AUTOSAR XML (schema 4-3-0)
package /Impl_SWC_FDC_ARPkg
  swc implementation Impl_SWC_FDC_type: programming-language=C, sw-version=1.0.0, vendor-id=0, behavior=SWC_FDC_type_IB
    code-descriptors:
      code SRC: artifact-descriptors=autosar-engineering-object={short-label=EngObject, category=SWSRC}
    resource consumption ResourceConsumption
      memory section MEM_SWC_FDC_CAL: size=0, sw-addrmethod=CAL, symbol=CAL
      memory section MEM_SWC_FDC_CODE: size=0, sw-addrmethod=CODE, symbol=CODE
package /SWC_FDC_ARPkg
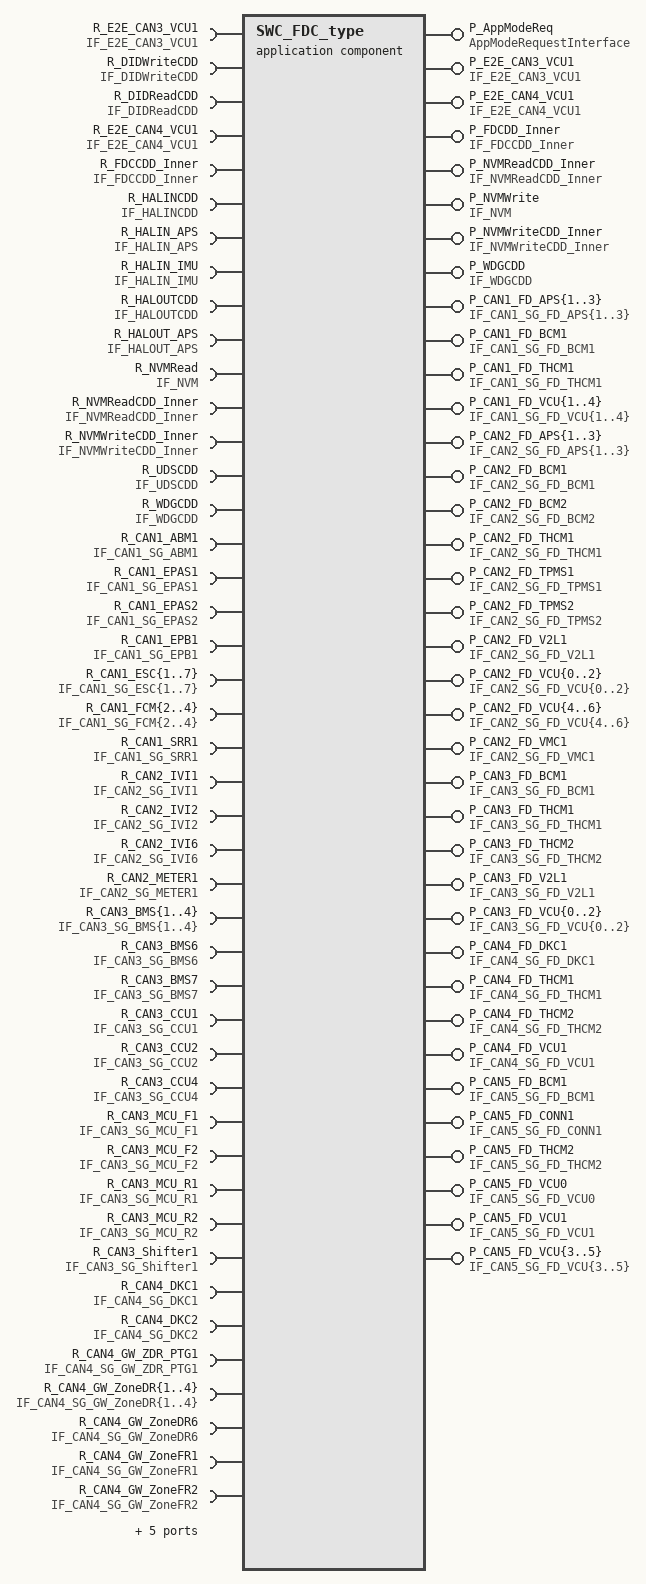
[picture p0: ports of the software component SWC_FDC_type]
  application sw component type SWC_FDC_type
    52 x provide port:
      P_AppModeReq: provided-interface=AppModeRequestInterface
      P_E2E_CAN3_VCU1: provided-interface=IF_E2E_CAN3_VCU1
      P_E2E_CAN4_VCU1: provided-interface=IF_E2E_CAN4_VCU1
      P_FDCDD_Inner: provided-interface=IF_FDCCDD_Inner
      P_NVMReadCDD_Inner: provided-interface=IF_NVMReadCDD_Inner
      P_NVMWrite: nv-provide-com-spec{ram-block-init-value=ValueSpecification_:256 x 0, rom-block-init-value=ValueSpecification_:256 x 0, variable=NV_FVTDataArray}, provided-interface=IF_NVM
      P_NVMWriteCDD_Inner: provided-interface=IF_NVMWriteCDD_Inner
      P_WDGCDD: provided-interface=IF_WDGCDD
      P_CAN1_FD_APS{1..3}: provided-interface=IF_CAN1_SG_FD_APS{1..3}
      P_CAN1_FD_BCM1: provided-interface=IF_CAN1_SG_FD_BCM1
      P_CAN1_FD_THCM1: provided-interface=IF_CAN1_SG_FD_THCM1
      P_CAN1_FD_VCU{1..4}: provided-interface=IF_CAN1_SG_FD_VCU{1..4}
      P_CAN2_FD_APS{1..3}: provided-interface=IF_CAN2_SG_FD_APS{1..3}
      P_CAN2_FD_BCM1: provided-interface=IF_CAN2_SG_FD_BCM1
      P_CAN2_FD_BCM2: provided-interface=IF_CAN2_SG_FD_BCM2
      P_CAN2_FD_THCM1: provided-interface=IF_CAN2_SG_FD_THCM1
      P_CAN2_FD_TPMS1: provided-interface=IF_CAN2_SG_FD_TPMS1
      P_CAN2_FD_TPMS2: provided-interface=IF_CAN2_SG_FD_TPMS2
      P_CAN2_FD_V2L1: provided-interface=IF_CAN2_SG_FD_V2L1
      P_CAN2_FD_VCU{0..2}: provided-interface=IF_CAN2_SG_FD_VCU{0..2}
      P_CAN2_FD_VCU{4..6}: provided-interface=IF_CAN2_SG_FD_VCU{4..6}
      P_CAN2_FD_VMC1: provided-interface=IF_CAN2_SG_FD_VMC1
      P_CAN3_FD_BCM1: provided-interface=IF_CAN3_SG_FD_BCM1
      P_CAN3_FD_THCM1: provided-interface=IF_CAN3_SG_FD_THCM1
      P_CAN3_FD_THCM2: provided-interface=IF_CAN3_SG_FD_THCM2
      P_CAN3_FD_V2L1: provided-interface=IF_CAN3_SG_FD_V2L1
      P_CAN3_FD_VCU{0..2}: provided-interface=IF_CAN3_SG_FD_VCU{0..2}
      P_CAN4_FD_DKC1: provided-interface=IF_CAN4_SG_FD_DKC1
      P_CAN4_FD_THCM1: provided-interface=IF_CAN4_SG_FD_THCM1
      P_CAN4_FD_THCM2: provided-interface=IF_CAN4_SG_FD_THCM2
      P_CAN4_FD_VCU1: provided-interface=IF_CAN4_SG_FD_VCU1
      P_CAN5_FD_BCM1: provided-interface=IF_CAN5_SG_FD_BCM1
      P_CAN5_FD_CONN1: provided-interface=IF_CAN5_SG_FD_CONN1
      P_CAN5_FD_THCM2: provided-interface=IF_CAN5_SG_FD_THCM2
      P_CAN5_FD_VCU0: provided-interface=IF_CAN5_SG_FD_VCU0
      P_CAN5_FD_VCU1: provided-interface=IF_CAN5_SG_FD_VCU1
      P_CAN5_FD_VCU{3..5}: provided-interface=IF_CAN5_SG_FD_VCU{3..5}
    63 x require port:
      R_E2E_CAN3_VCU1: required-interface=IF_E2E_CAN3_VCU1
      R_DIDWriteCDD: required-interface=IF_DIDWriteCDD
      R_DIDReadCDD: required-interface=IF_DIDReadCDD
      R_E2E_CAN4_VCU1: required-interface=IF_E2E_CAN4_VCU1
      R_FDCCDD_Inner: required-interface=IF_FDCCDD_Inner
      R_HALINCDD: required-interface=IF_HALINCDD
      R_HALIN_APS: required-interface=IF_HALIN_APS
      R_HALIN_IMU: required-interface=IF_HALIN_IMU
      R_HALOUTCDD: required-interface=IF_HALOUTCDD
      R_HALOUT_APS: required-interface=IF_HALOUT_APS
      R_NVMRead: nv-require-com-spec{init-value=256 x 0, variable=NV_FVTDataArray}, required-interface=IF_NVM
      R_NVMReadCDD_Inner: required-interface=IF_NVMReadCDD_Inner
      R_NVMWriteCDD_Inner: required-interface=IF_NVMWriteCDD_Inner
      R_UDSCDD: required-interface=IF_UDSCDD
      R_WDGCDD: required-interface=IF_WDGCDD
      R_CAN1_ABM1: required-interface=IF_CAN1_SG_ABM1
      R_CAN1_EPAS1: required-interface=IF_CAN1_SG_EPAS1
      R_CAN1_EPAS2: required-interface=IF_CAN1_SG_EPAS2
      R_CAN1_EPB1: required-interface=IF_CAN1_SG_EPB1
      R_CAN1_ESC{1..7}: required-interface=IF_CAN1_SG_ESC{1..7}
      R_CAN1_FCM{2..4}: required-interface=IF_CAN1_SG_FCM{2..4}
      R_CAN1_SRR1: required-interface=IF_CAN1_SG_SRR1
      R_CAN2_IVI1: required-interface=IF_CAN2_SG_IVI1
      R_CAN2_IVI2: required-interface=IF_CAN2_SG_IVI2
      R_CAN2_IVI6: required-interface=IF_CAN2_SG_IVI6
      R_CAN2_METER1: required-interface=IF_CAN2_SG_METER1
      R_CAN3_BMS{1..4}: required-interface=IF_CAN3_SG_BMS{1..4}
      R_CAN3_BMS6: required-interface=IF_CAN3_SG_BMS6
      R_CAN3_BMS7: required-interface=IF_CAN3_SG_BMS7
      R_CAN3_CCU1: required-interface=IF_CAN3_SG_CCU1
      R_CAN3_CCU2: required-interface=IF_CAN3_SG_CCU2
      R_CAN3_CCU4: required-interface=IF_CAN3_SG_CCU4
      R_CAN3_MCU_F1: required-interface=IF_CAN3_SG_MCU_F1
      R_CAN3_MCU_F2: required-interface=IF_CAN3_SG_MCU_F2
      R_CAN3_MCU_R1: required-interface=IF_CAN3_SG_MCU_R1
      R_CAN3_MCU_R2: required-interface=IF_CAN3_SG_MCU_R2
      R_CAN3_Shifter1: required-interface=IF_CAN3_SG_Shifter1
      R_CAN4_DKC1: required-interface=IF_CAN4_SG_DKC1
      R_CAN4_DKC2: required-interface=IF_CAN4_SG_DKC2
      R_CAN4_GW_ZDR_PTG1: required-interface=IF_CAN4_SG_GW_ZDR_PTG1
      R_CAN4_GW_ZoneDR{1..4}: required-interface=IF_CAN4_SG_GW_ZoneDR{1..4}
      R_CAN4_GW_ZoneDR6: required-interface=IF_CAN4_SG_GW_ZoneDR6
      R_CAN4_GW_ZoneFR1: required-interface=IF_CAN4_SG_GW_ZoneFR1
      R_CAN4_GW_ZoneFR2: required-interface=IF_CAN4_SG_GW_ZoneFR2
      R_CAN4_Zone_Dr_SCP: required-interface=IF_CAN4_SG_Zone_Dr_SCP
      R_CAN4_Zone_Dr_THCM: required-interface=IF_CAN4_SG_Zone_Dr_THCM
      R_CAN4_Zone_Dr_VCU: required-interface=IF_CAN4_SG_Zone_Dr_VCU
      R_CAN4_Zone_Fr_THCM: required-interface=IF_CAN4_SG_Zone_Fr_THCM
      R_CAN5_TBOX1: required-interface=IF_CAN5_SG_TBOX1
    behavior SWC_FDC_type_IB: data-type-mapping=AppModeTypeMap, handle-termination-and-restart=NO-SUPPORT
      9 x timing event:
        TE_100ms: start-on-event=run_SWC_FDC_Tx_100ms, period=0.1
        TE_20ms: start-on-event=run_SWC_FDC_Tx_20ms, period=0.02
        TE_500ms: start-on-event=run_SWC_FDC_Tx_500ms, period=0.5
        TE_5000ms: start-on-event=run_SWC_FDC_Tx_5000ms, period=5
        TE_10ms: start-on-event=run_SWC_FDC_Tx_10ms, period=0.01
        TE_5ms: start-on-event=run_SWC_FDC_RxTx_5ms, period=0.005
        TE_CDD_10ms: start-on-event=run_SWC_FDC_CDD_10ms, period=0.01
        TE_PAS_1ms: start-on-event=run_SWC_FDC_PAS_1ms, period=0.001
        TE_UDS_10ms: start-on-event=run_SWC_FDC_UDS_10ms, period=0.01
      8 x operation invoked event:
        oie_P_E2E_CAN3_VCU1_CSOP_Write_CAN3_VCU1: start-on-event=run_SWC_FDC_E2E_Write_CAN3VCU1, operation=P_E2E_CAN3_VCU1.CSOP_Write_CAN3_VCU1
        oie_P_E2E_CAN4_VCU1_CSOP_Write_CAN4_VCU1: start-on-event=run_SWC_FDC_E2E_Write_CAN4VCU1, operation=P_E2E_CAN4_VCU1.CSOP_Write_CAN4_VCU1
        oie_P_FDCDD_Inner_CSOP_FDC_AppCallSleep: start-on-event=run_SWC_FDC_AppCallSleep, operation=P_FDCDD_Inner.CSOP_FDC_AppCallSleep
        oie_P_NVMReadCDD_Inner_NVM_ReadOperation: start-on-event=run_SWC_FDC_NvmRead, operation=P_NVMReadCDD_Inner.NVM_ReadOperation
        oie_P_NVMWriteCDD_Inner_NVM_WriteOperation: start-on-event=run_SWC_FDC_NvmWrite, operation=P_NVMWriteCDD_Inner.NVM_WriteOperation
        oie_P_WDGCDD_CSOP_Call_WDG_AppEnd: start-on-event=run_SWC_FDC_AppCallWDG_End, operation=P_WDGCDD.CSOP_Call_WDG_AppEnd
        oie_P_WDGCDD_CSOP_Call_WDG_AppStart: start-on-event=run_SWC_FDC_AppCallWDG_StartUp, operation=P_WDGCDD.CSOP_Call_WDG_AppStart
        oie_P_WDGCDD_CSOP_Call_Watchdog: start-on-event=run_SWC_FDC_AppCallWDG, operation=P_WDGCDD.CSOP_Call_Watchdog
      explicit-inter-runnable-variables:
        50 x data:
          IRV_ms10_CAN1_SG_FD_APS3: type=DT_CAN1_SG_FD_APS3
          IRV_ms10_CAN1_SG_FD_VCU2: type=DT_CAN1_SG_FD_VCU2
          IRV_ms10_CAN1_SG_FD_VCU3: type=DT_CAN1_SG_FD_VCU3
          IRV_ms10_CAN2_SG_FD_APS3: type=DT_CAN2_SG_FD_APS3
          IRV_ms10_CAN2_SG_FD_VCU2: type=DT_CAN2_SG_FD_VCU2
          IRV_ms10_CAN3_SG_FD_VCU0: type=DT_CAN3_SG_FD_VCU0
          IRV_ms10_CAN3_SG_FD_VCU2: type=DT_CAN3_SG_FD_VCU2
          IRV_ms10_CAN5_SG_FD_VCU3: type=DT_CAN5_SG_FD_VCU3
          IRV_ms100_CAN{1..4}_SG_FD_THCM1: type=DT_CAN{1..4}_SG_FD_THCM1
          IRV_ms20_CAN1_SG_FD_APS1: type=DT_CAN1_SG_FD_APS1
          IRV_ms20_CAN1_SG_FD_APS2: type=DT_CAN1_SG_FD_APS2
          IRV_ms20_CAN2_SG_FD_APS1: type=DT_CAN2_SG_FD_APS1
          IRV_ms20_CAN2_SG_FD_APS2: type=DT_CAN2_SG_FD_APS2
          IRV_ms500_CAN2_SG_FD_VCU5: type=DT_CAN2_SG_FD_VCU5
          IRV_ms500_CAN5_SG_FD_VCU5: type=DT_CAN5_SG_FD_VCU5
          IRV_ms5000_CAN2_SG_FD_VCU6: type=DT_CAN2_SG_FD_VCU6
          IRV_E2E_CAN3_SG_FD_VCU1: type=DT_CAN3_SG_FD_VCU1
          IRV_E2E_CAN4_SG_FD_VCU1: type=DT_CAN4_SG_FD_VCU1
          IRV_f32_ApsOutVehSpdSig: type=float32
          IRV_u16Array4_ApsInDist: type=u16_APSArray4_type
          IRV_u8Array12_ApsInUssSta: type=u8_USSArray12_type
          IRV_u8Array256_NvmReadArray: type=u8_FVTNVMArray256_type
          IRV_u8Array256_NvmWriteArray: type=u8_FVTNVMArray256_type
          IRV_u8Array8_ApsInLevel: type=u8_APSLevelArray8_type
          IRV_u8Array8_PasInDist: type=u8_PASArray8_type
          IRV_u8Array9_TPMSData: type=u8_TPMSDataArray9_type
          IRV_u8_ApsInPASChime: type=uint8
          IRV_u8_ApsInSensorLayout: type=uint8
          IRV_u8_ApsInSysFailSta: type=uint8
          IRV_u8_ApsInSysMode: type=uint8
          IRV_u8_ApsOutGearPosnSig: type=uint8
          IRV_u8_ApsOutSendChrgPlugSta: type=uint8
          IRV_u8_ApsOutSetFrSensorOnCmd: type=uint8
          IRV_u8_ApsOutSetFrSensorSwTOCmd: type=uint8
          IRV_u8_ApsOutSetVehSpdTOCmd: type=uint8
          IRV_u8_CTDSW: type=uint8
          IRV_u8_CrashSignal: type=uint8
          IRV_u8_DrDoorSW: type=uint8
          IRV_u8_HazardSW: type=uint8
          IRV_u8_HoodSW: type=uint8
          IRV_u8_PsDoorSW: type=uint8
          IRV_u8_RLDoorSW: type=uint8
          IRV_u8_RRDoorSW: type=uint8
          IRV_u8_SeatSW: type=uint8
          IRV_u8_TPMSDataInSta: type=boolean
          IRV_u8_TailgateSW: type=uint8
          IRV_u8_TrunkHanSW: type=uint8
      port-api-options:
        enable-take-address=false, indirect-api=false, port=P_FDCDD_Inner
        enable-take-address=false, indirect-api=false, port=P_NVMReadCDD_Inner
        enable-take-address=false, indirect-api=false, port=P_NVMWriteCDD_Inner
        enable-take-address=false, indirect-api=false, port=P_E2E_CAN3_VCU1
        enable-take-address=false, indirect-api=false, port=P_E2E_CAN4_VCU1
        enable-take-address=false, indirect-api=false, port=P_WDGCDD
      17 x runnable:
        run_SWC_FDC_Tx_100ms
          data-send-points:
            4 x access:
              dsp_CAN{1..4}_SG_FD_THCM1: accessed-variable=P_CAN{1..4}_FD_THCM1.CAN{1..4}_SG_FD_THCM1
          read-local-variables:
            4 x access:
              IRV_ms100_CAN{1..4}_SG_FD_THCM1: accessed-variable=IRV_ms100_CAN{1..4}_SG_FD_THCM1
        run_SWC_FDC_Tx_20ms
          data-send-points:
            4 x access:
              dsp_CAN1_SG_FD_APS1: accessed-variable=P_CAN1_FD_APS1.CAN1_SG_FD_APS1
              dsp_CAN1_SG_FD_APS2: accessed-variable=P_CAN1_FD_APS2.CAN1_SG_FD_APS2
              dsp_CAN2_SG_FD_APS1: accessed-variable=P_CAN2_FD_APS1.CAN2_SG_FD_APS1
              dsp_CAN2_SG_FD_APS2: accessed-variable=P_CAN2_FD_APS2.CAN2_SG_FD_APS2
          read-local-variables:
            4 x access:
              IRV_ms20_CAN1_SG_FD_APS1: accessed-variable=IRV_ms20_CAN1_SG_FD_APS1
              IRV_ms20_CAN1_SG_FD_APS2: accessed-variable=IRV_ms20_CAN1_SG_FD_APS2
              IRV_ms20_CAN2_SG_FD_APS1: accessed-variable=IRV_ms20_CAN2_SG_FD_APS1
              IRV_ms20_CAN2_SG_FD_APS2: accessed-variable=IRV_ms20_CAN2_SG_FD_APS2
        run_SWC_FDC_Tx_500ms
          data-send-points:
            access dsp_CAN2_SG_FD_VCU5: accessed-variable=P_CAN2_FD_VCU5.CAN2_SG_FD_VCU5
            access dsp_CAN5_SG_FD_VCU5: accessed-variable=P_CAN5_FD_VCU5.CAN5_SG_FD_VCU5
          read-local-variables:
            access IRV_ms500_CAN2_SG_FD_VCU5: accessed-variable=IRV_ms500_CAN2_SG_FD_VCU5
            access IRV_ms500_CAN5_SG_FD_VCU5: accessed-variable=IRV_ms500_CAN5_SG_FD_VCU5
        run_SWC_FDC_Tx_5000ms
          data-send-points:
            access dsp_CAN2_SG_FD_VCU6: accessed-variable=P_CAN2_FD_VCU6.CAN2_SG_FD_VCU6
          read-local-variables:
            access IRV_ms5000_CAN2_SG_FD_VCU6: accessed-variable=IRV_ms5000_CAN2_SG_FD_VCU6
        run_SWC_FDC_AppCallSleep
          data-send-points:
            access dsp_requestedMode: accessed-variable=P_AppModeReq.requestedMode
        run_SWC_FDC_AppCallWDG
        run_SWC_FDC_AppCallWDG_End
        run_SWC_FDC_AppCallWDG_StartUp
        run_SWC_FDC_CDD_10ms
          sync call scp_CSOP_HALINCDD_IOEXPANDER: operation=R_HALINCDD.CSOP_HALINCDD_IOEXPANDER, timeout=0.0
          written-local-variables:
            11 x access:
              IRV_u8_CTDSW: accessed-variable=IRV_u8_CTDSW
              IRV_u8_CrashSignal: accessed-variable=IRV_u8_CrashSignal
              IRV_u8_DrDoorSW: accessed-variable=IRV_u8_DrDoorSW
              IRV_u8_HazardSW: accessed-variable=IRV_u8_HazardSW
              IRV_u8_HoodSW: accessed-variable=IRV_u8_HoodSW
              IRV_u8_PsDoorSW: accessed-variable=IRV_u8_PsDoorSW
              IRV_u8_RLDoorSW: accessed-variable=IRV_u8_RLDoorSW
              IRV_u8_RRDoorSW: accessed-variable=IRV_u8_RRDoorSW
              IRV_u8_SeatSW: accessed-variable=IRV_u8_SeatSW
              IRV_u8_TailgateSW: accessed-variable=IRV_u8_TailgateSW
              IRV_u8_TrunkHanSW: accessed-variable=IRV_u8_TrunkHanSW
        run_SWC_FDC_E2E_Write_CAN3VCU1
          data-send-points:
            access dsp_CAN3_SG_FD_VCU1: accessed-variable=P_CAN3_FD_VCU1.CAN3_SG_FD_VCU1
          read-local-variables:
            access IRV_E2E_CAN3_SG_FD_VCU1: accessed-variable=IRV_E2E_CAN3_SG_FD_VCU1
        run_SWC_FDC_E2E_Write_CAN4VCU1
          data-send-points:
            access dsp_CAN4_SG_FD_VCU1: accessed-variable=P_CAN4_FD_VCU1.CAN4_SG_FD_VCU1
          read-local-variables:
            access IRV_E2E_CAN4_SG_FD_VCU1: accessed-variable=IRV_E2E_CAN4_SG_FD_VCU1
        run_SWC_FDC_NvmRead
          data-receive-point-by-arguments:
            access drparg_NV_FVTDataArray: accessed-variable=R_NVMRead.NV_FVTDataArray
          written-local-variables:
            access IRV_u8Array256_NvmReadArray: accessed-variable=IRV_u8Array256_NvmReadArray
        run_SWC_FDC_NvmWrite
          data-send-points:
            access dsp_NV_FVTDataArray: accessed-variable=P_NVMWrite.NV_FVTDataArray
          read-local-variables:
            access IRV_u8Array256_NvmWriteArray: accessed-variable=IRV_u8Array256_NvmWriteArray
        run_SWC_FDC_PAS_1ms
          sync call scp_CSOP_PAS_Handler: operation=R_HALINCDD.CSOP_PAS_Handler, timeout=0.0
        run_SWC_FDC_RxTx_5ms
          data-receive-point-by-arguments:
            48 x access:
              drparg_CAN1_SG_ABM1: accessed-variable=R_CAN1_ABM1.CAN1_SG_ABM1
              drparg_CAN1_SG_EPAS1: accessed-variable=R_CAN1_EPAS1.CAN1_SG_EPAS1
              drparg_CAN1_SG_EPAS2: accessed-variable=R_CAN1_EPAS2.CAN1_SG_EPAS2
              drparg_CAN1_SG_EPB1: accessed-variable=R_CAN1_EPB1.CAN1_SG_EPB1
              drparg_CAN1_SG_ESC{1..7}: accessed-variable=R_CAN1_ESC{1..7}.CAN1_SG_ESC{1..7}
              drparg_CAN1_SG_FCM{2..4}: accessed-variable=R_CAN1_FCM{2..4}.CAN1_SG_FCM{2..4}
              drparg_CAN1_SG_SRR1: accessed-variable=R_CAN1_SRR1.CAN1_SG_SRR1
              drparg_CAN2_SG_IVI1: accessed-variable=R_CAN2_IVI1.CAN2_SG_IVI1
              drparg_CAN2_SG_IVI2: accessed-variable=R_CAN2_IVI2.CAN2_SG_IVI2
              drparg_CAN2_SG_IVI6: accessed-variable=R_CAN2_IVI6.CAN2_SG_IVI6
              drparg_CAN2_SG_METER1: accessed-variable=R_CAN2_METER1.CAN2_SG_METER1
              drparg_CAN3_SG_BMS{1..4}: accessed-variable=R_CAN3_BMS{1..4}.CAN3_SG_BMS{1..4}
              drparg_CAN3_SG_BMS6: accessed-variable=R_CAN3_BMS6.CAN3_SG_BMS6
              drparg_CAN3_SG_BMS7: accessed-variable=R_CAN3_BMS7.CAN3_SG_BMS7
              drparg_CAN3_SG_CCU1: accessed-variable=R_CAN3_CCU1.CAN3_SG_CCU1
              drparg_CAN3_SG_CCU2: accessed-variable=R_CAN3_CCU2.CAN3_SG_CCU2
              drparg_CAN3_SG_CCU4: accessed-variable=R_CAN3_CCU4.CAN3_SG_CCU4
              drparg_CAN3_SG_MCU_F1: accessed-variable=R_CAN3_MCU_F1.CAN3_SG_MCU_F1
              drparg_CAN3_SG_MCU_F2: accessed-variable=R_CAN3_MCU_F2.CAN3_SG_MCU_F2
              drparg_CAN3_SG_MCU_R1: accessed-variable=R_CAN3_MCU_R1.CAN3_SG_MCU_R1
              drparg_CAN3_SG_MCU_R2: accessed-variable=R_CAN3_MCU_R2.CAN3_SG_MCU_R2
              drparg_CAN3_SG_Shifter1: accessed-variable=R_CAN3_Shifter1.CAN3_SG_Shifter1
              drparg_CAN4_SG_DKC1: accessed-variable=R_CAN4_DKC1.CAN4_SG_DKC1
              drparg_CAN4_SG_DKC2: accessed-variable=R_CAN4_DKC2.CAN4_SG_DKC2
              drparg_CAN4_SG_GW_ZDR_PTG1: accessed-variable=R_CAN4_GW_ZDR_PTG1.CAN4_SG_GW_ZDR_PTG1
              drparg_CAN4_SG_GW_ZoneDR{1..4}: accessed-variable=R_CAN4_GW_ZoneDR{1..4}.CAN4_SG_GW_ZoneDR{1..4}
              drparg_CAN4_SG_GW_ZoneDR6: accessed-variable=R_CAN4_GW_ZoneDR6.CAN4_SG_GW_ZoneDR6
              drparg_CAN4_SG_GW_ZoneFR1: accessed-variable=R_CAN4_GW_ZoneFR1.CAN4_SG_GW_ZoneFR1
              drparg_CAN4_SG_GW_ZoneFR2: accessed-variable=R_CAN4_GW_ZoneFR2.CAN4_SG_GW_ZoneFR2
              drparg_CAN4_SG_Zone_Dr_SCP: accessed-variable=R_CAN4_Zone_Dr_SCP.CAN4_SG_Zone_Dr_SCP
              drparg_CAN4_SG_Zone_Dr_THCM: accessed-variable=R_CAN4_Zone_Dr_THCM.CAN4_SG_Zone_Dr_THCM
              drparg_CAN4_SG_Zone_Dr_VCU: accessed-variable=R_CAN4_Zone_Dr_VCU.CAN4_SG_Zone_Dr_VCU
              drparg_CAN4_SG_Zone_Fr_THCM: accessed-variable=R_CAN4_Zone_Fr_THCM.CAN4_SG_Zone_Fr_THCM
              drparg_CAN5_SG_TBOX1: accessed-variable=R_CAN5_TBOX1.CAN5_SG_TBOX1
          data-send-points:
            23 x access:
              dsp_CAN1_SG_FD_BCM1: accessed-variable=P_CAN1_FD_BCM1.CAN1_SG_FD_BCM1
              dsp_CAN1_SG_FD_VCU1: accessed-variable=P_CAN1_FD_VCU1.CAN1_SG_FD_VCU1
              dsp_CAN1_SG_FD_VCU4: accessed-variable=P_CAN1_FD_VCU4.CAN1_SG_FD_VCU4
              dsp_CAN2_SG_FD_BCM1: accessed-variable=P_CAN2_FD_BCM1.CAN2_SG_FD_BCM1
              dsp_CAN2_SG_FD_BCM2: accessed-variable=P_CAN2_FD_BCM2.CAN2_SG_FD_BCM2
              dsp_CAN2_SG_FD_TPMS1: accessed-variable=P_CAN2_FD_TPMS1.CAN2_SG_FD_TPMS1
              dsp_CAN2_SG_FD_TPMS2: accessed-variable=P_CAN2_FD_TPMS2.CAN2_SG_FD_TPMS2
              dsp_CAN2_SG_FD_V2L1: accessed-variable=P_CAN2_FD_V2L1.CAN2_SG_FD_V2L1
              dsp_CAN2_SG_FD_VCU0: accessed-variable=P_CAN2_FD_VCU0.CAN2_SG_FD_VCU0
              dsp_CAN2_SG_FD_VCU1: accessed-variable=P_CAN2_FD_VCU1.CAN2_SG_FD_VCU1
              dsp_CAN2_SG_FD_VCU4: accessed-variable=P_CAN2_FD_VCU4.CAN2_SG_FD_VCU4
              dsp_CAN2_SG_FD_VMC1: accessed-variable=P_CAN2_FD_VMC1.CAN2_SG_FD_VMC1
              dsp_CAN3_SG_FD_BCM1: accessed-variable=P_CAN3_FD_BCM1.CAN3_SG_FD_BCM1
              dsp_CAN3_SG_FD_THCM2: accessed-variable=P_CAN3_FD_THCM2.CAN3_SG_FD_THCM2
              dsp_CAN3_SG_FD_V2L1: accessed-variable=P_CAN3_FD_V2L1.CAN3_SG_FD_V2L1
              dsp_CAN4_SG_FD_DKC1: accessed-variable=P_CAN4_FD_DKC1.CAN4_SG_FD_DKC1
              dsp_CAN4_SG_FD_THCM2: accessed-variable=P_CAN4_FD_THCM2.CAN4_SG_FD_THCM2
              dsp_CAN5_SG_FD_BCM1: accessed-variable=P_CAN5_FD_BCM1.CAN5_SG_FD_BCM1
              dsp_CAN5_SG_FD_CONN1: accessed-variable=P_CAN5_FD_CONN1.CAN5_SG_FD_CONN1
              dsp_CAN5_SG_FD_THCM2: accessed-variable=P_CAN5_FD_THCM2.CAN5_SG_FD_THCM2
              dsp_CAN5_SG_FD_VCU0: accessed-variable=P_CAN5_FD_VCU0.CAN5_SG_FD_VCU0
              dsp_CAN5_SG_FD_VCU1: accessed-variable=P_CAN5_FD_VCU1.CAN5_SG_FD_VCU1
              dsp_CAN5_SG_FD_VCU4: accessed-variable=P_CAN5_FD_VCU4.CAN5_SG_FD_VCU4
          read-local-variables:
            22 x access:
              IRV_u16Array4_ApsInDist: accessed-variable=IRV_u16Array4_ApsInDist
              IRV_u8Array12_ApsInUssSta: accessed-variable=IRV_u8Array12_ApsInUssSta
              IRV_u8Array256_NvmReadArray: accessed-variable=IRV_u8Array256_NvmReadArray
              IRV_u8Array8_ApsInLevel: accessed-variable=IRV_u8Array8_ApsInLevel
              IRV_u8Array8_PasInDist: accessed-variable=IRV_u8Array8_PasInDist
              IRV_u8Array9_TPMSData: accessed-variable=IRV_u8Array9_TPMSData
              IRV_u8_ApsInPASChime: accessed-variable=IRV_u8_ApsInPASChime
              IRV_u8_ApsInSensorLayout: accessed-variable=IRV_u8_ApsInSensorLayout
              IRV_u8_ApsInSysFailSta: accessed-variable=IRV_u8_ApsInSysFailSta
              IRV_u8_ApsInSysMode: accessed-variable=IRV_u8_ApsInSysMode
              IRV_u8_CTDSW: accessed-variable=IRV_u8_CTDSW
              IRV_u8_CrashSignal: accessed-variable=IRV_u8_CrashSignal
              IRV_u8_DrDoorSW: accessed-variable=IRV_u8_DrDoorSW
              IRV_u8_HazardSW: accessed-variable=IRV_u8_HazardSW
              IRV_u8_HoodSW: accessed-variable=IRV_u8_HoodSW
              IRV_u8_PsDoorSW: accessed-variable=IRV_u8_PsDoorSW
              IRV_u8_RLDoorSW: accessed-variable=IRV_u8_RLDoorSW
              IRV_u8_RRDoorSW: accessed-variable=IRV_u8_RRDoorSW
              IRV_u8_SeatSW: accessed-variable=IRV_u8_SeatSW
              IRV_u8_TPMSDataInSta: accessed-variable=IRV_u8_TPMSDataInSta
              IRV_u8_TailgateSW: accessed-variable=IRV_u8_TailgateSW
              IRV_u8_TrunkHanSW: accessed-variable=IRV_u8_TrunkHanSW
          63 x sync call, all with timeout=0.0:
            scp_CSOP_AnyNmID: operation=R_HALINCDD.CSOP_AnyNmID
            scp_CSOP_AppNmStateReq: operation=R_HALOUTCDD.CSOP_AppNmStateReq
            scp_CSOP_GetAcoreRebootCmd: operation=R_HALINCDD.CSOP_GetAcoreRebootCmd
            scp_CSOP_SetAcoreRebootCmdACK: operation=R_HALOUTCDD.CSOP_SetAcoreRebootCmdACK
            scp_CSOP_CAN{1..5}BusOff: operation=R_HALINCDD.CSOP_CAN{1..5}BusOff
            scp_CSOP_ApsGetData: operation=R_HALIN_APS.CSOP_ApsGetData
            scp_CSOP_ApsSetData: operation=R_HALOUT_APS.CSOP_ApsSetData
            scp_CSOP_ApsSetTimeout: operation=R_HALOUT_APS.CSOP_ApsSetTimeout
            scp_CSOP_Call_WDG_AppEnd: operation=R_WDGCDD.CSOP_Call_WDG_AppEnd
            scp_CSOP_Call_WDG_AppStart: operation=R_WDGCDD.CSOP_Call_WDG_AppStart
            scp_CSOP_Call_Watchdog: operation=R_WDGCDD.CSOP_Call_Watchdog
            scp_CSOP_DIDgetDKCdata: operation=R_HALINCDD.CSOP_DIDgetDKCdata
            scp_CSOP_DIDgetXWDdata: operation=R_HALINCDD.CSOP_DIDgetXWDdata
            scp_CSOP_DKCDecrypt: operation=R_HALINCDD.CSOP_DKCDecrypt
            scp_CSOP_DdmClearDTCNotifica: operation=R_UDSCDD.CSOP_DdmClearDTCNotification
            scp_CSOP_DdmRestartOperation: operation=R_UDSCDD.CSOP_DdmRestartOperationCycle
            scp_CSOP_FDC_AppCallSleep: operation=R_FDCCDD_Inner.CSOP_FDC_AppCallSleep
            scp_CSOP_GetACoreReadyToSleep: operation=R_HALINCDD.CSOP_GetAcoreReadyToSleep
            scp_CSOP_GetAuxBattVoltage: operation=R_HALINCDD.CSOP_GetAuxBattVoltage
            scp_CSOP_GetBootReason: operation=R_HALINCDD.CSOP_GetBootReason
            scp_CSOP_GetEvccAplusPwrUpReq: operation=R_HALINCDD.CSOP_GetEvccAplusPwrUpReq
            scp_CSOP_GetHWID: operation=R_HALINCDD.u8Array4_HWID
            scp_CSOP_GetNmState: operation=R_HALINCDD.CSOP_GetNmState
            scp_CSOP_GetNvmProtectState: operation=R_HALINCDD.CSOP_GetNvmProtectState
            scp_CSOP_GetSWID: operation=R_HALINCDD.CSOP_GetSWID
            scp_CSOP_GetVinpAllowMoveThd: operation=R_HALINCDD.CSOP_GetVinpAllowMoveThdOta
            scp_CSOP_GetVinpPwrReqOta: operation=R_HALINCDD.CSOP_GetVinpPwrReqOta
            scp_CSOP_GetWISR: operation=R_HALINCDD.CSOP_GetWISR
            scp_CSOP_HALINCDD_DIRECT: operation=R_HALINCDD.CSOP_HALINCDD_DIRECT
            scp_CSOP_IMUGetOffsetVal: operation=R_HALIN_IMU.CSOP_IMUGetOffsetVal
            scp_CSOP_IMUGetSixAxisVal: operation=R_HALIN_IMU.CSOP_IMUGetSixAxisVal
            scp_CSOP_IMUSetSta: operation=R_HALIN_IMU.CSOP_IMUSetSta
            scp_CSOP_IVIReset: operation=R_HALOUTCDD.CSOP_IVIReset
            scp_CSOP_SetDTCStatus: operation=R_UDSCDD.CSOP_SetDTCStatus
            scp_CSOP_SetSysPwrStat: operation=R_HALOUTCDD.CSOP_SetSysPwrStat
            scp_CSOP_SleepRequest: operation=R_HALOUTCDD.CSOP_SleepRequest
            scp_CSOP_Write_CAN3_VCU1: operation=R_E2E_CAN3_VCU1.CSOP_Write_CAN3_VCU1
            scp_CSOP_Write_CAN4_VCU1: operation=R_E2E_CAN4_VCU1.CSOP_Write_CAN4_VCU1
            scp_NVM_ReadOperation: operation=R_NVMReadCDD_Inner.NVM_ReadOperation
            scp_CSOP_DIDGet_XWDMode: operation=R_DIDReadCDD.CSOP_DIDGet_XWDMode
            scp_CSOP_DIDSet_XWDMode: operation=R_DIDWriteCDD.CSOP_DIDSet_XWDMode
            scp_CSOP_DIDGet_DKCKey: operation=R_DIDReadCDD.CSOP_DIDGet_DKCKey
            scp_CSOP_DIDSet_DKCKey: operation=R_DIDWriteCDD.CSOP_DIDSet_DKCKey
            scp_CSOP_DIDGet_DynoMode: operation=R_DIDReadCDD.CSOP_DIDGet_DynoMode
            scp_CSOP_DIDSet_DynoMode: operation=R_DIDWriteCDD.CSOP_DIDSet_DynoMode
            scp_CSOP_DIDSet_LFSensorID: operation=R_DIDWriteCDD.CSOP_DIDSet_LFSensorID
            scp_CSOP_DIDSet_RFSensorID: operation=R_DIDWriteCDD.CSOP_DIDSet_RFSensorID
            scp_CSOP_DIDSet_LRSensorID: operation=R_DIDWriteCDD.CSOP_DIDSet_LRSensorID
            scp_CSOP_DIDSet_RRSensorID: operation=R_DIDWriteCDD.CSOP_DIDSet_RRSensorID
            scp_CSOP_DIDSet_WhlPres: operation=R_DIDWriteCDD.CSOP_DIDSet_WhlPres
            scp_CSOP_DIDSet_WhlTmp: operation=R_DIDWriteCDD.CSOP_DIDSet_WhlTmp
            scp_CSOP_DIDSet_WhlSensorBattSta: operation=R_DIDWriteCDD.CSOP_DIDSet_WhlSensorBattSta
            scp_CSOP_DIDSet_LFLowPresThre: operation=R_DIDWriteCDD.CSOP_DIDSet_LFLowPresThre
            scp_CSOP_DIDSet_RFLowPresThre: operation=R_DIDWriteCDD.CSOP_DIDSet_RFLowPresThre
            scp_CSOP_DIDSet_LRLowPresThre: operation=R_DIDWriteCDD.CSOP_DIDSet_LRLowPresThre
            scp_CSOP_DIDSet_RRLowPresThre: operation=R_DIDWriteCDD.CSOP_DIDSet_RRLowPresThre
            scp_CSOP_DIDSet_SensorMode: operation=R_DIDWriteCDD.CSOP_DIDSet_SensorMode
            scp_CSOP_DIDSet_TPMSLearnSta: operation=R_DIDWriteCDD.CSOP_DIDSet_TPMSLearnSta
            scp_NVM_WriteOperation: operation=R_NVMWriteCDD_Inner.NVM_WriteOperation
          written-local-variables:
            28 x access:
              IRV_ms10_CAN1_SG_FD_APS3: accessed-variable=IRV_ms10_CAN1_SG_FD_APS3
              IRV_ms10_CAN1_SG_FD_VCU2: accessed-variable=IRV_ms10_CAN1_SG_FD_VCU2
              IRV_ms10_CAN1_SG_FD_VCU3: accessed-variable=IRV_ms10_CAN1_SG_FD_VCU3
              IRV_ms10_CAN2_SG_FD_APS3: accessed-variable=IRV_ms10_CAN2_SG_FD_APS3
              IRV_ms10_CAN2_SG_FD_VCU2: accessed-variable=IRV_ms10_CAN2_SG_FD_VCU2
              IRV_ms10_CAN3_SG_FD_VCU0: accessed-variable=IRV_ms10_CAN3_SG_FD_VCU0
              IRV_ms10_CAN3_SG_FD_VCU2: accessed-variable=IRV_ms10_CAN3_SG_FD_VCU2
              IRV_ms10_CAN5_SG_FD_VCU3: accessed-variable=IRV_ms10_CAN5_SG_FD_VCU3
              IRV_ms100_CAN{1..4}_SG_FD_THCM1: accessed-variable=IRV_ms100_CAN{1..4}_SG_FD_THCM1
              IRV_ms20_CAN1_SG_FD_APS1: accessed-variable=IRV_ms20_CAN1_SG_FD_APS1
              IRV_ms20_CAN1_SG_FD_APS2: accessed-variable=IRV_ms20_CAN1_SG_FD_APS2
              IRV_ms20_CAN2_SG_FD_APS1: accessed-variable=IRV_ms20_CAN2_SG_FD_APS1
              IRV_ms20_CAN2_SG_FD_APS2: accessed-variable=IRV_ms20_CAN2_SG_FD_APS2
              IRV_ms500_CAN2_SG_FD_VCU5: accessed-variable=IRV_ms500_CAN2_SG_FD_VCU5
              IRV_ms500_CAN5_SG_FD_VCU5: accessed-variable=IRV_ms500_CAN5_SG_FD_VCU5
              IRV_ms5000_CAN2_SG_FD_VCU6: accessed-variable=IRV_ms5000_CAN2_SG_FD_VCU6
              IRV_E2E_CAN3_SG_FD_VCU1: accessed-variable=IRV_E2E_CAN3_SG_FD_VCU1
              IRV_E2E_CAN4_SG_FD_VCU1: accessed-variable=IRV_E2E_CAN4_SG_FD_VCU1
              IRV_f32_ApsOutVehSpdSig: accessed-variable=IRV_f32_ApsOutVehSpdSig
              IRV_u8Array256_NvmWriteArray: accessed-variable=IRV_u8Array256_NvmWriteArray
              IRV_u8_ApsOutGearPosnSig: accessed-variable=IRV_u8_ApsOutGearPosnSig
              IRV_u8_ApsOutSendChrgPlugSta: accessed-variable=IRV_u8_ApsOutSendChrgPlugSta
              IRV_u8_ApsOutSetFrSensorOnCmd: accessed-variable=IRV_u8_ApsOutSetFrSensorOnCmd
              IRV_u8_ApsOutSetFrSensorSwTOCmd: accessed-variable=IRV_u8_ApsOutSetFrSensorSwTOCmd
              IRV_u8_ApsOutSetVehSpdTOCmd: accessed-variable=IRV_u8_ApsOutSetVehSpdTOCmd
        run_SWC_FDC_Tx_10ms
          data-send-points:
            8 x access:
              dsp_CAN1_SG_FD_APS3: accessed-variable=P_CAN1_FD_APS3.CAN1_SG_FD_APS3
              dsp_CAN1_SG_FD_VCU2: accessed-variable=P_CAN1_FD_VCU2.CAN1_SG_FD_VCU2
              dsp_CAN1_SG_FD_VCU3: accessed-variable=P_CAN1_FD_VCU3.CAN1_SG_FD_VCU3
              dsp_CAN2_SG_FD_APS3: accessed-variable=P_CAN2_FD_APS3.CAN2_SG_FD_APS3
              dsp_CAN2_SG_FD_VCU2: accessed-variable=P_CAN2_FD_VCU2.CAN2_SG_FD_VCU2
              dsp_CAN3_SG_FD_VCU0: accessed-variable=P_CAN3_FD_VCU0.CAN3_SG_FD_VCU0
              dsp_CAN3_SG_FD_VCU2: accessed-variable=P_CAN3_FD_VCU2.CAN3_SG_FD_VCU2
              dsp_CAN5_SG_FD_VCU3: accessed-variable=P_CAN5_FD_VCU3.CAN5_SG_FD_VCU3
          read-local-variables:
            14 x access:
              IRV_ms10_CAN1_SG_FD_APS3: accessed-variable=IRV_ms10_CAN1_SG_FD_APS3
              IRV_ms10_CAN1_SG_FD_VCU2: accessed-variable=IRV_ms10_CAN1_SG_FD_VCU2
              IRV_ms10_CAN1_SG_FD_VCU3: accessed-variable=IRV_ms10_CAN1_SG_FD_VCU3
              IRV_ms10_CAN2_SG_FD_APS3: accessed-variable=IRV_ms10_CAN2_SG_FD_APS3
              IRV_ms10_CAN2_SG_FD_VCU2: accessed-variable=IRV_ms10_CAN2_SG_FD_VCU2
              IRV_ms10_CAN3_SG_FD_VCU0: accessed-variable=IRV_ms10_CAN3_SG_FD_VCU0
              IRV_ms10_CAN3_SG_FD_VCU2: accessed-variable=IRV_ms10_CAN3_SG_FD_VCU2
              IRV_ms10_CAN5_SG_FD_VCU3: accessed-variable=IRV_ms10_CAN5_SG_FD_VCU3
              IRV_f32_ApsOutVehSpdSig: accessed-variable=IRV_f32_ApsOutVehSpdSig
              IRV_u8_ApsOutGearPosnSig: accessed-variable=IRV_u8_ApsOutGearPosnSig
              IRV_u8_ApsOutSendChrgPlugSta: accessed-variable=IRV_u8_ApsOutSendChrgPlugSta
              IRV_u8_ApsOutSetFrSensorOnCmd: accessed-variable=IRV_u8_ApsOutSetFrSensorOnCmd
              IRV_u8_ApsOutSetFrSensorSwTOCmd: accessed-variable=IRV_u8_ApsOutSetFrSensorSwTOCmd
              IRV_u8_ApsOutSetVehSpdTOCmd: accessed-variable=IRV_u8_ApsOutSetVehSpdTOCmd
          6 x sync call, all with timeout=0.0:
            scp_CSOP_ApsGetDist: operation=R_HALIN_APS.CSOP_ApsGetDist
            scp_CSOP_ApsGetDistLevel: operation=R_HALIN_APS.CSOP_ApsGetDistLevel
            scp_CSOP_ApsGetUssSta: operation=R_HALIN_APS.CSOP_ApsGetUssSta
            scp_CSOP_ApsOutput: operation=R_HALOUT_APS.CSOP_ApsOutput
            scp_CSOP_GetAPSOtherStatus: operation=R_HALIN_APS.CSOP_ApsGetOtherStatus
            scp_CSOP_TPMS_GetRawData: operation=R_HALINCDD.CSOP_TPMS_GetRawData
          written-local-variables:
            10 x access:
              IRV_u16Array4_ApsInDist: accessed-variable=IRV_u16Array4_ApsInDist
              IRV_u8Array12_ApsInUssSta: accessed-variable=IRV_u8Array12_ApsInUssSta
              IRV_u8Array8_ApsInLevel: accessed-variable=IRV_u8Array8_ApsInLevel
              IRV_u8Array8_PasInDist: accessed-variable=IRV_u8Array8_PasInDist
              IRV_u8Array9_TPMSData: accessed-variable=IRV_u8Array9_TPMSData
              IRV_u8_ApsInPASChime: accessed-variable=IRV_u8_ApsInPASChime
              IRV_u8_ApsInSensorLayout: accessed-variable=IRV_u8_ApsInSensorLayout
              IRV_u8_ApsInSysFailSta: accessed-variable=IRV_u8_ApsInSysFailSta
              IRV_u8_ApsInSysMode: accessed-variable=IRV_u8_ApsInSysMode
              IRV_u8_TPMSDataInSta: accessed-variable=IRV_u8_TPMSDataInSta
        run_SWC_FDC_UDS_10ms
          sync call scp_CSOP_UDS_Main: operation=R_HALINCDD.CSOP_UDS_Main, timeout=0.0
